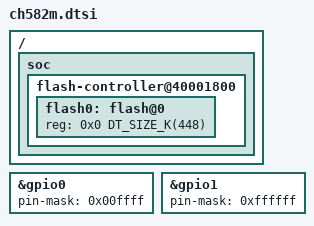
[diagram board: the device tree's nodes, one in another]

#include <wch/ch57x/ch58x.dtsi>

/ {
	soc {
		flash-controller@40001800 {

			flash0: flash@0 {
				reg = <0x0 DT_SIZE_K(448)>;
				//erase-block-size = <DT_SIZE_K(1)>;
			};
		};
	};
};

&gpio0 {
	pin-mask = <0x00ffff>;
};

&gpio1 {
	pin-mask = <0xffffff>;
};


